# MKL43Z4 register map
Vendor: Freescale Semiconductor, Inc.; Series: Kinetis_L; File version: 1.6
CPU: CM0PLUS r0p0, little endian, no MPU, no FPU, VTOR, 2 interrupt priority bits
Registers are 8-bit, read-write, reset 0x0 unless marked. A register's access mark holds for its fields unless they carry their own. Offsets are from the block's base; [hi:lo] are bit positions; {n}, {i} and the like mark numbered series.

## PTA — General Purpose Input/Output
Base 0x400FF000; register names take the prefix GPIOA_
0x00 PDOR 32-bit — Port Data Output Register
  [31:0] PDO — Port Data Output
    0=Logic level 0 is driven on pin, provided pin is configured for general-purpose output; 1=Logic level 1 is driven on pin, provided pin is configured for general-purpose output
0x04 PSOR 32-bit wo — Port Set Output Register
  [31:0] PTSO — Port Set Output
    0=Corresponding bit in PDORn does not change; 1=Corresponding bit in PDORn is set to logic 1
0x08 PCOR 32-bit wo — Port Clear Output Register
  [31:0] PTCO — Port Clear Output
    0=Corresponding bit in PDORn does not change; 1=Corresponding bit in PDORn is cleared to logic 0
0x0C PTOR 32-bit wo — Port Toggle Output Register
  [31:0] PTTO — Port Toggle Output
    0=Corresponding bit in PDORn does not change; 1=Corresponding bit in PDORn is set to the inverse of its existing logic state
0x10 PDIR 32-bit ro — Port Data Input Register
  [31:0] PDI — Port Data Input
    0=Pin logic level is logic 0, or is not configured for use by digital function; 1=Pin logic level is logic 1
0x14 PDDR 32-bit — Port Data Direction Register
  [31:0] PDD — Port Data Direction
    0=Pin is configured as general-purpose input, for the GPIO function; 1=Pin is configured as general-purpose output, for the GPIO function

## PTB — General Purpose Input/Output
Base 0x400FF040; register names take the prefix GPIOB_
Registers as PTA.

## PTC — General Purpose Input/Output
Base 0x400FF080; register names take the prefix GPIOC_
Registers as PTA; these are added or differ:
0x08 PCOR 32-bit wo — Port Clear Output Register
  [31:0] PTCO — Port Clear Output
    0=Corresponding bit in PDORn does not change; 1=Corresponding bit in PDORn is cleared to logic 0

## PTD — General Purpose Input/Output
Base 0x400FF0C0; register names take the prefix GPIOD_
Registers as PTA.

## PTE — General Purpose Input/Output
Base 0x400FF100; register names take the prefix GPIOE_
Registers as PTA.

## MTB — Micro Trace Buffer
Base 0xF0000000; register names take the prefix MTB_
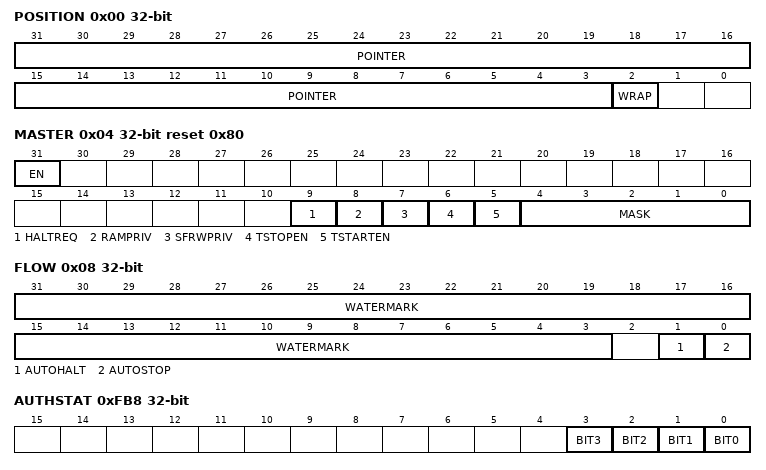
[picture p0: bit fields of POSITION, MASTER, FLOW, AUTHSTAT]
0x00 POSITION 32-bit (reset mask 0x3) — MTB Position Register
  [31:3] POINTER — Trace Packet Address Pointer[28:0]
  [2] WRAP
0x04 MASTER 32-bit reset 0x80 (reset mask 0xFFFFFFE0) — MTB Master Register
  [31] EN — Main Trace Enable
  [9] HALTREQ — Halt Request
  [8] RAMPRIV — RAM Privilege
  [7] SFRWPRIV — Special Function Register Write Privilege
  [6] TSTOPEN — Trace Stop Input Enable
  [5] TSTARTEN — Trace Start Input Enable
  [4:0] MASK
0x08 FLOW 32-bit (reset mask 0x4) — MTB Flow Register
  [31:3] WATERMARK — WATERMARK[28:0]
  [1] AUTOHALT
  [0] AUTOSTOP
0x0C BASE 32-bit ro reset not defined — MTB Base Register
  [31:0] BASEADDR
0xF00 MODECTRL 32-bit ro — Integration Mode Control Register
0xFA0 TAGSET 32-bit ro — Claim TAG Set Register
0xFA4 TAGCLEAR 32-bit ro — Claim TAG Clear Register
0xFB0 LOCKACCESS 32-bit ro
0xFB4 LOCKSTAT 32-bit ro — Lock Status Register
0xFB8 AUTHSTAT 32-bit ro — Authentication Status Register
  [n] BIT{n} (n=0..3)
0xFBC DEVICEARCH 32-bit ro reset 0x47700A31 — Device Architecture Register
0xFC8 DEVICECFG 32-bit ro — Device Configuration Register
0xFCC DEVICETYPID 32-bit ro reset 0x31 — Device Type Identifier Register
0xFD0 PERIPHID{x} (x=4,5,6,7,0,1,2,3; step 0x4) 32-bit ro reset not defined — Peripheral ID Register
  [31:0] PERIPHID
{0xFF0+4i} COMPID{i} (i=0..3) 32-bit ro reset not defined — Component ID Register
  [31:0] COMPID — Component ID
